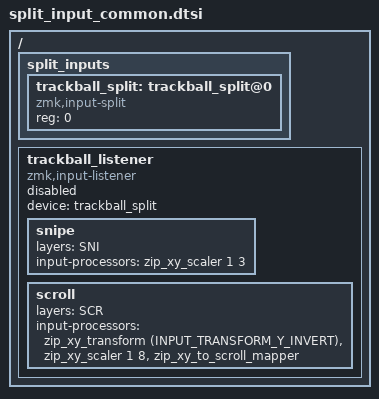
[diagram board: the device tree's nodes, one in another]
## WIP - based on https://github.com/eXsoR65/Charybdis_Nano-Config/blob/main/config/west.yml
#include <dt-bindings/zmk/input_transform.h>
#include <input/processors.dtsi>

#define DEF 0
#define NAV 1
#define SMN 2
#define FUN 3
#define MOU 4
#define SCR 5
#define SNI 6

/ {
  split_inputs {
    #address-cells = <1>;
    #size-cells = <0>;

    trackball_split: trackball_split@0 {
      compatible = "zmk,input-split";
      reg = <0>;
    };
  };

  trackball_listener: trackball_listener {
    compatible = "zmk,input-listener";
    status = "disabled";
    device = <&trackball_split>;

    snipe {
      layers = <SNI>;
      input-processors = <&zip_xy_scaler 1 3>;
    };

    scroll {
      layers = <SCR>;
      input-processors = <&zip_xy_transform (INPUT_TRANSFORM_Y_INVERT)>, <&zip_xy_scaler 1 8>, <&zip_xy_to_scroll_mapper>;
    };
  };
};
